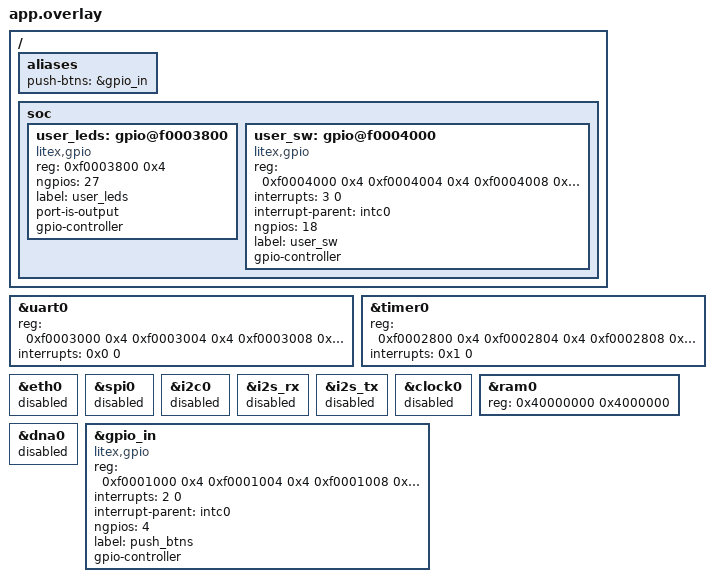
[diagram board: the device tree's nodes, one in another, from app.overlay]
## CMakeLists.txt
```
# SPDX-License-Identifier: Apache-2.0

cmake_minimum_required(VERSION 3.20.0)

find_package(Zephyr REQUIRED HINTS $ENV{ZEPHYR_BASE})
project(de2-115)

target_sources(app PRIVATE src/main.c)
```

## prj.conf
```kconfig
CONFIG_UART_LITEUART=y
CONFIG_LITEX_TIMER=y
CONFIG_ETH_LITEETH=n
CONFIG_SPI_LITESPI=n
CONFIG_I2C_LITEX=n
CONFIG_I2S_LITEX=n
CONFIG_I2S_LITEX=n
CONFIG_CLOCK_CONTROL_LITEX=n
CONFIG_LITEX_CSR_DATA_WIDTH=32
CONFIG_GPIO=y
CONFIG_SYS_CLOCK_TICKS_PER_SEC=1
```

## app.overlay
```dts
&uart0 {
    reg = <0xf0003000 0x4
        0xf0003004 0x4
        0xf0003008 0x4
        0xf000300c 0x4
        0xf0003010 0x4
        0xf0003014 0x4
        0xf0003018 0x4
        0xf000301c 0x4>;
    reg-names = "rxtx",
        "txfull",
        "rxempty",
        "ev_status",
        "ev_pending",
        "ev_enable",
        "txempty",
        "rxfull";
    interrupts = <0x0 0>;
};
&timer0 {
    reg = <0xf0002800 0x4
        0xf0002804 0x4
        0xf0002808 0x4
        0xf000280c 0x4
        0xf0002810 0x4
        0xf0002814 0x4
        0xf0002818 0x4
        0xf000281c 0x4
        0xf0002820 0x4
        0xf0002824 0x8>;
    reg-names = "load",
        "reload",
        "en",
        "update_value",
        "value",
        "ev_status",
        "ev_pending",
        "ev_enable",
        "uptime_latch",
        "uptime_cycles";
    interrupts = <0x1 0>;
};
&eth0 {
    status = "disabled";
};
&spi0 {
    status = "disabled";
};
&i2c0 {
    status = "disabled";
};
&i2s_rx {
    status = "disabled";
};
&i2s_tx {
    status = "disabled";
};
&clock0 {
    status = "disabled";
};
&ram0 {
    reg = <0x40000000 0x4000000>;
};
&dna0 {
    status = "disabled";
};


&gpio_in {
	compatible = "litex,gpio";
	reg = <0xf0001000 0x4
		0xf0001004 0x4
		0xf0001008 0x4
		0xf0001010 0x4
		0xf0001014 0x4>;
	interrupts = <2 0>;
	interrupt-parent = <&intc0>;
	reg-names = "base",
		"irq_mode",
		"irq_edge",
		"irq_pend",
		"irq_en";
	ngpios = <4>;
	label = "push_btns";
	status = "okay";
	#gpio-cells = <2>;
	gpio-controller;
};

/ {
	aliases {
		push-btns = &gpio_in;
	};
	soc {
		user_leds: gpio@f0003800 {
			compatible = "litex,gpio";
			reg = <0xf0003800 0x4>;
			reg-names = "led";
			ngpios = <27>;
			label = "user_leds";
			port-is-output;
			status = "okay";
			#gpio-cells = <2>;
			gpio-controller;
		};

		user_sw: gpio@f0004000 {
			compatible = "litex,gpio";
			reg = <0xf0004000 0x4
				0xf0004004 0x4
				0xf0004008 0x4
				0xf0004010 0x4
				0xf0004014 0x4>;
			interrupts = <3 0>;
			interrupt-parent = <&intc0>;
			ngpios = <18>;
			status = "okay";
			label = "user_sw";
			#gpio-cells = <2>;
			gpio-controller;
			reg-names = "base",
				"irq_mode",
				"irq_edge",
				"irq_pend",
				"irq_en";
		};
	};
};
```

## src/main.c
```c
#include <zephyr/zephyr.h>
#include <zephyr/drivers/gpio.h>

// TODO this probably deservers a litex,control compatible on DTS
// (or properly import the header generated by litex)
#define CTRL_RESET 0xf0000000L

#define N_LEDS DT_PROP(DT_NODELABEL(user_leds), ngpios)

const struct device *leds;
const struct device *push_btns;
const struct device *user_sw;
static uint32_t led_counter;

static struct gpio_callback push_btn_gpio_cb;
static struct gpio_callback user_sw_gpio_cb;

static void led_timer_handler(struct k_timer *timer)
{
	ARG_UNUSED(timer);

	int i;
	for (i = 0; i < N_LEDS; i++)
		gpio_pin_set(leds, i, (led_counter & (1 << i)));

	led_counter = (led_counter + 1) % (1 << N_LEDS);
}

K_TIMER_DEFINE(led_timer, led_timer_handler, NULL);

void push_btn_cb(const struct device *dev, struct gpio_callback *cb,
		 uint32_t pin)
{
	// TODO: check a way to reboot to the bootloader on the press of
	// some button.
	printk("Button pressed, pin: %u, device: %p\n", pin, dev);
	if (pin == 8)
		*((uint32_t *)CTRL_RESET) = 1;
}

void user_sw_cb(const struct device *dev, struct gpio_callback *cb,
		uint32_t pin)
{
	printk("Switch moved, pin: %u, device: %p\n", pin, dev);
}

void main(void)
{
	int ret, i;

	printk("main started!\n");

	leds = device_get_binding("user_leds");
	push_btns = device_get_binding("push_btns");
	user_sw = device_get_binding("user_sw");
	printk("Got leds dev: %p push btns dev: %p user switches %p\n",
	       leds, push_btns, user_sw);

	// TODO get those from device tree
	for (i = 0; i < 18; i++) {
		ret = gpio_pin_configure(user_sw, i, GPIO_INPUT);
		ret =  gpio_pin_interrupt_configure(user_sw, i,
						    GPIO_INT_EDGE_BOTH);
	}
	gpio_init_callback(&user_sw_gpio_cb, user_sw_cb, BIT(18) - 1);
	ret = gpio_add_callback(user_sw, &user_sw_gpio_cb);

	for (i = 0; i < 4; i++) {
		ret = gpio_pin_configure(push_btns, i, GPIO_INPUT);
		ret =  gpio_pin_interrupt_configure(push_btns, i,
						    GPIO_INT_EDGE_BOTH);
	}
	gpio_init_callback(&push_btn_gpio_cb, push_btn_cb, 0xf);
	ret = gpio_add_callback(push_btns, &push_btn_gpio_cb);

	k_timer_start(&led_timer, K_MSEC(2000), K_MSEC(2000));
}
```
